# RZN2H register map
Vendor: Renesas Electronics Corporation; Series: RZN; File version: 1.00.00
CPU: other r0p0, little endian, MPU, no FPU, VTOR, 4 interrupt priority bits, 624 interrupts
Registers are 32-bit, read-write, reset 0x0 unless marked. A register's access mark holds for its fields unless they carry their own. Offsets are from the block's base; [hi:lo] are bit positions; lines under a group give offsets from that group; {n}, {i} and the like mark numbered series; 'fields as' and 'values as' point back to an identical list; <NAME> marks a mode.

## ADC122 — 12-Bit A/D converter 2
Base 0x80008000
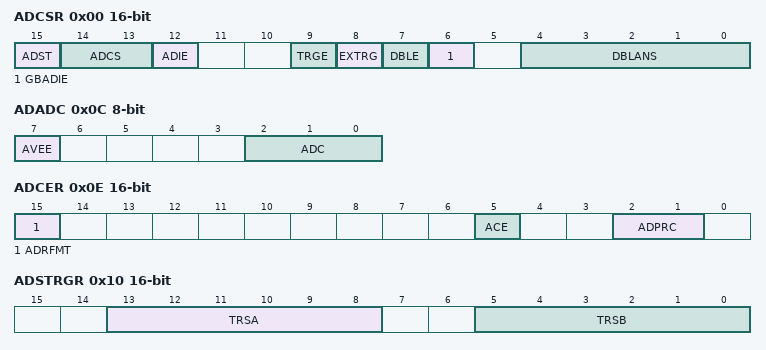
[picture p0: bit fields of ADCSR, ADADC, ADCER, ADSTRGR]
0x00 ADCSR 16-bit — A/D Control Register
  [15] ADST — A/D conversion Start
    0=Stops A/D conversion process; 1=Starts A/D conversion process
  [14:13] ADCS — Scan Mode Select
    0=Single scan mode; 1=Group scan mode; 2=Continuous scan mode; 3=Setting prohibited
  [12] ADIE — Scan End Interrupt Enable
    0=Disables ADCn_ADI interrupt generation upon scan completion; 1=Enables ADCn_ADI interrupt generation upon scan completion
  [9] TRGE — Trigger Start Enable
    0=Disables A/D conversion to be started by the synchronous or asynchronous trigger; 1=Enables A/D conversion to be started by the synchronous or asynchronous trigger
  [8] EXTRG — Trigger Select
    0=A/D conversion is started by a synchronous trigger (MTU3, ELC); 1=A/D conversion is started by the asynchronous trigger (ADTRGn#)
  [7] DBLE — Double Trigger Mode Select
    0=Deselects double trigger mode; 1=Selects double trigger mode
  [6] GBADIE — Group B Scan End Interrupt Enable
    0=Disables ADCn_GBADI interrupt generation upon group B scan completion; 1=Enables ADCn_GBADI interrupt generation upon group B scan completion
  [4:0] DBLANS — Double Trigger Channel Select
0x04 ADANSA0 16-bit — A/D Channel Select Register A0
  [15:0] ANSA0 — A/D conversion Analog input Channel Select
    0=ch0-ch15 are not subjected to conversion; 1=ch0-ch15 are subjected to conversion
0x08 ADADS0 16-bit — A/D-Converted Value Addition/Average Function Channel Select Register 0
  [15:0] ADS0 — A/D-Converted Value Addition/Average Channel Select
    0=A/D-converted value addition/average mode for ch0 to ch15 is not selected; 1=A/D-converted value addition/average mode for ch0 to ch15 is selected
0x0C ADADC 8-bit — A/D-Converted Value Addition/Average Count Select Register
  [7] AVEE — Average Mode Enable
    0=Addition mode is selected; 1=Average mode is selected
  [2:0] ADC — Addition Count Select
    0=1-time conversion (no addition; same as normal conversion); 1=2-time conversion (addition once); 2=3-time conversion (addition twice); 3=4-time conversion (addition three times); 5=16-time conversion (addition 15 times); other=Others (Setting is prohibited)
0x0E ADCER 16-bit — A/D Control Extended Register
  [15] ADRFMT — A/D Data Register Format Select
    0=Right-alignment is selected for the A/D data register format; 1=Left-alignment is selected for the A/D data register format
  [5] ACE — A/D Data Register Automatic Clearing Enable
    0=Disables automatic clearing; 1=Enables automatic clearing
  [2:1] ADPRC — A/D Conversion Accuracy Specify
    0=A/D conversion is performed with 12-bit accuracy; other=Others (Setting prohibited)
0x10 ADSTRGR 16-bit — A/D Conversion Start Trigger Select Register
  [13:8] TRSA — A/D Conversion Start Trigger Select
  [5:0] TRSB — A/D Conversion Start Trigger Select for Group B
0x14 ADANSB0 16-bit — A/D Channel Select Register B0
  [15:0] ANSB0 — A/D Conversion Analog Input Channel Select
    values as ADANSA0.ANSA0
0x18 ADDBLDR 16-bit ro — A/D Data Duplication Register
  [15:0] DBLDR — The result of A/D conversion in response to the second trigger in double trigger mode.
{0x20+2i} ADDR{i} (i=0..14) 16-bit ro — A/D Data Register {i}
  [15:0] DR — The result of A/D conversion (n: Number of channel)
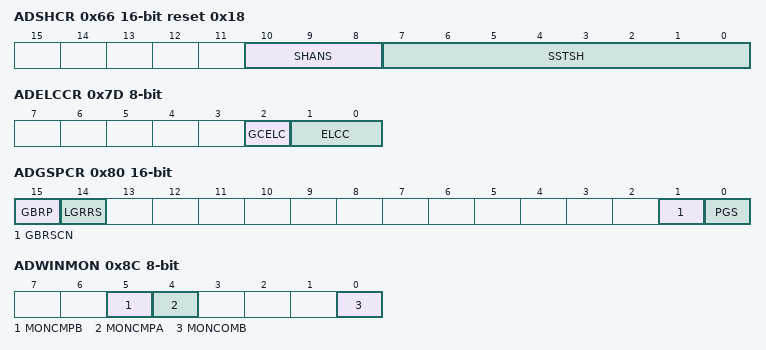
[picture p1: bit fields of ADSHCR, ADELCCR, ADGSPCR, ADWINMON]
0x66 ADSHCR 16-bit reset 0x18 — A/D Sample and Hold Control Register
  [10:8] SHANS — Sample and hold use or bypass select for ch0-2
    0=Bypass S/H; 1=Use S/H
  [7:0] SSTSH — Sample and hold period setting
0x7D ADELCCR 8-bit — A/D Event Link Control Register
  [2] GCELC — Event control bit for Group C
    0=Enable the setting of ELCC[1:0]; 1=Disable the setting of ELCC[1:0] and output event signal at the end of group scan of group C
  [1:0] ELCC — Event link control bits
    0=Output event signal at the end of scan except the end of group scan of group A, B; 1=Output event signal at the end of group scan of group B; 0b1x=Output event signal at the end of scan
0x80 ADGSPCR 16-bit — A/D Group Scan Priority Control Register
  [15] GBRP — Group B Single Scan Continuous Start
    0=Single scan for group B is not continuously activated; 1=Single scan for group B is continuously activated
  [14] LGRRS — Restart Channel Select
    0=Restart scan with first channel; 1=Restart scan with suspended channel
  [1] GBRSCN — Group B Restart Setting
    0=Scanning for group is not restarted when priority control is performed; 1=Scanning for group is restarted when priority control is performed
  [0] PGS — Group Priority Control Setting
    0=Operation is without group priority control; 1=Operation is with group priority control
0x84 ADDBLDRA 16-bit ro — A/D Data Duplication Register A
  [15:0] DBLDRA — The result of A/D conversion during extended operation in double trigger mode
0x86 ADDBLDRB 16-bit ro — A/D Data Duplication Register B
  [15:0] DBLDRB — The result of A/D conversion during extended operation in double trigger mode
0x8C ADWINMON 8-bit ro — A/D Compare Function Window A/B Status Monitoring Register
  [5] MONCMPB — Comparing result monitor for window B
    0=Window B comparing condition does not match; 1=Window B comparing condition match
  [4] MONCMPA — Comparing result monitor for window A
    0=Window A comparing condition does not match; 1=Window A comparing condition match
  [0] MONCOMB — Combination result monitor
    0=Window A/B combination condition does not match; 1=Window A/B combination condition match
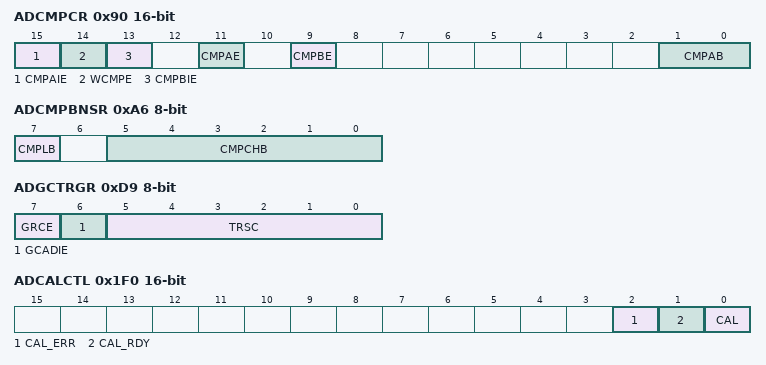
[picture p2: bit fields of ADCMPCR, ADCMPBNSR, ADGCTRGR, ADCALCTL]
0x90 ADCMPCR 16-bit — A/D Compare Function Control Register
  [15] CMPAIE — Compare window A Interrupt Enable
    0=Generation of an ADCn_CMPAI interrupt in response to matches with a condition for comparison is disabled; 1=Generation of an ADCn_CMPAI interrupt in response to matches with a condition for comparison is enabled
  [14] WCMPE — Window Function enable
    0=Window function disabled; 1=Window function enabled
  [13] CMPBIE — Compare window B Interrupt Enable
    0=Generation of an ADCn_CMPBI interrupt in response to matches with a condition for comparison is disabled; 1=Generation of an ADCn_CMPBI interrupt in response to matches with a condition for comparison is enabled
  [11] CMPAE — Window A operation permission
    0=Window A is not in operation. Output of ADCn_WCMPM/ADCn_WCMPUM is not permitted.; 1=Window A is in operation
  [9] CMPBE — Window B operation permission
    0=Window B is not in operation. Output of ADCn_WCMPM/ADCn_WCMPUM is not permitted.; 1=Window B is in operation
  [1:0] CMPAB — Window A/B combination condition setting
    0=Output ADCn_WCMPM when window A comparison condition match OR window B comparison condition match, otherwise output ADCn_WCMPUM; 1=Output ADCn_WCMPM when window A comparison condition match EXOR window B comparison condition match, otherwise output ADCn_WCMPUM; 2=Output ADCn_WCMPM when window A comparison condition match AND window B comparison condition match, otherwise output ADCn_WCMPUM; 3=Setting prohibited
0x94 ADCMPANSR0 16-bit — A/D Compare Function Window A Channel Select Register 0
  [15:0] CMPCHA0 — Window A Channel Select
    0=Channel is not target; 1=Channel is target
0x98 ADCMPLR0 16-bit — A/D Compare Function Window A Comparison Condition Setting Register 0
  [15:0] CMPLCHA0 — Window A comparison condition for target channel (ch0-15) setting
    0=When window function is disabled (ADCMPCR.WCMPE = 0): ADCMPDR0 register value > A/D-converted value When window function is enabled (ADCMPCR.WCMPE = 1): A/D-converted value < ADCMPDR0 register value or ADCMPDR1 register value < A/D-converted value; 1=When window function is disabled (ADCMPCR.WCMPE = 0): ADCMPDR0 register value < A/D-converted value When window function is enabled (ADCMPCR.WCMPE = 1): ADCMPDR0 register value < A/D-converted value < ADCMPDR1 register value
0x9C ADCMPDR0 16-bit — A/D Comparison Function Window A Lower Level Setting Register
  [15:0] CMPLLA — Reference data setting when using the compare function window A
0x9E ADCMPDR1 16-bit — AD Comparison Function Window A Upper Level Setting Register
  [15:0] CMPULA — Reference data setting when using the compare function window A
0xA0 ADCMPSR0 16-bit — A/D Comparison Function Window A Channel Status Register 0
  [15:0] CMPSTCHA0 — Window A Status Flag
    0=Condition does not match; 1=Condition matches
0xA6 ADCMPBNSR 8-bit — A/D Compare Function Window B Channel Select Register
  [7] CMPLB — Window B Comparison Condition Setting
    0=When window function is disabled (ADCMPCR.WCMPE = 0): ADWINLLB register value > A/D-converted value. When window function is enabled (ADCMPCR.WCMPE = 1): A/D-converted value < ADWINLLB register value or ADWINULB register value < A/D-converted value.; 1=When window function is disabled (ADCMPCR.WCMPE = 0): ADWINLLB register value < A/D-converted value. When window function is enabled (ADCMPCR.WCMPE = 1): ADWINLLB register value < A/D-converted value < ADWINULB register value.
  [5:0] CMPCHB — Window B Channel Select
0xA8 ADWINLLB 16-bit — A/D Compare Function Window B Lower-Side Level Setting Register
  [15:0] CMPLLB — Reference lower data setting when using the compare function window B
0xAA ADWINULB 16-bit — A/D Compare Function Window B Upper-Side Level Setting Register
  [15:0] CMPULB — Reference upper data setting when using the compare function window B
0xAC ADCMPBSR 8-bit — A/D Compare Function Window B Status Register
  [0] CMPSTB — Window B Flag
    0=Comparison conditions are not met; 1=Comparison conditions are met
0xD4 ADANSC0 16-bit — A/D Channel Select Register C0
  [15:0] ANSC0 — A/D-Converted Channel Select for Group C in Group Scan Mode
    0=Channel is not target; 1=Channel is target
0xD9 ADGCTRGR 8-bit — A/D Group C Trigger Select Register
  [7] GRCE — Group C A/D Conversion Enable
    0=Group C A/D conversion is disabled; 1=Group C A/D conversion is enabled
  [6] GCADIE — Group C Scan Completion Interrupt Enable
    0=Group C scan completed interrupt (ADCn_GCADI) is disabled; 1=Group C scan completed interrupt (ADCn_GCADI) is enabled
  [5:0] TRSC — Group C A/D Conversion Start Trigger Select
{0xE0+i} ADSSTR{i} (i=0..14) 8-bit reset 0xB — A/D Sampling State Register {i}
  [7:0] SST — Sampling Time Setting
0x1F0 ADCALCTL 16-bit — A/D Calibration Control Register
  [2] CAL_ERR ro — Calibration Result
    0=Normal end; 1=Abnormal end
  [1] CAL_RDY ro — Calibration Status
    0=Calibration is not started, or on progress; 1=Calibration is completed
  [0] CAL — Calibration Start
    0=No calibration; 1=Start calibration

## ADC120 — 12-Bit A/D converter 0
Base 0x90014000
Same registers: ADC121 0x90014400
Registers as ADC122, without ADDR*, ADSSTR*; these are added or differ:
{0x20+2i} ADDR{i} (i=0..3) 16-bit ro — A/D Data Register {i}
  [15:0] DR — The result of A/D conversion (n: Number of channel)
{0xE0+i} ADSSTR{i} (i=0..3) 8-bit reset 0xB — A/D Sampling State Register {i}
  [7:0] SST — Sampling Time Setting
